VERSION "Emergency_System_CAN_Compat_v2.0"

NS_ :

BS_:

BU_: SIL_TEST_CTRL CHASSIS_GW ACCEL_CTRL BRAKE_CTRL STEERING_CTRL ADAS_WARN_CTRL Vector__XXX VEHICLE_BASE_TEST_CTRL EMS_POLICE_TX EMS_AMB_TX EMS_ALERT_RX BODY_GW BCM_AMBIENT_CTRL HAZARD_CTRL WINDOW_CTRL DRIVER_STATE_CTRL WARN_ARB_MGR INFOTAINMENT_GW IVI_GW NAV_CONTEXT_MGR CLU_HMI_CTRL CLUSTER_BASE_CTRL ENGINE_CTRL TRANSMISSION_CTRL DOMAIN_GW_ROUTER

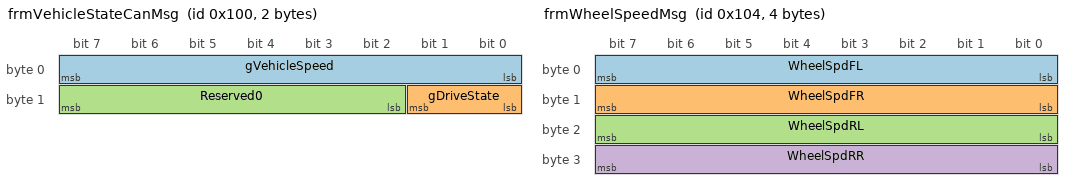
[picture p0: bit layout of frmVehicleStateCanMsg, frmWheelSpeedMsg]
BO_ 256 frmVehicleStateCanMsg: 2 SIL_TEST_CTRL
 SG_ gVehicleSpeed : 0|8@1+ (1,0) [0|255] "km/h" CHASSIS_GW,ADAS_WARN_CTRL
 SG_ gDriveState   : 8|2@1+ (1,0) [0|3]   ""     CHASSIS_GW,ADAS_WARN_CTRL
 SG_ Reserved0     : 10|6@1+ (1,0) [0|0]  ""     Vector__XXX

BO_ 257 frmSteeringCanMsg: 1 SIL_TEST_CTRL
 SG_ SteeringInput : 0|1@1+ (1,0) [0|1] "" CHASSIS_GW,STEERING_CTRL
 SG_ Reserved0     : 1|7@1+ (1,0) [0|0] "" Vector__XXX

BO_ 258 frmPedalInputCanMsg: 2 SIL_TEST_CTRL
 SG_ AccelPedal       : 0|8@1+ (1,0) [0|100] "%" ACCEL_CTRL
 SG_ BrakePedal       : 8|8@1+ (1,0) [0|100] "%" BRAKE_CTRL

BO_ 259 frmSteeringStateCanMsg: 1 CHASSIS_GW
 SG_ SteeringState    : 0|2@1+ (1,0) [0|3] "" STEERING_CTRL
 SG_ Reserved0        : 2|6@1+ (1,0) [0|0] "" Vector__XXX

BO_ 260 frmWheelSpeedMsg: 4 CHASSIS_GW
 SG_ WheelSpdFL       : 0|8@1+ (1,0) [0|255] "km/h" ACCEL_CTRL,BRAKE_CTRL,STEERING_CTRL
 SG_ WheelSpdFR       : 8|8@1+ (1,0) [0|255] "km/h" ACCEL_CTRL,BRAKE_CTRL,STEERING_CTRL
 SG_ WheelSpdRL       : 16|8@1+ (1,0) [0|255] "km/h" ACCEL_CTRL,BRAKE_CTRL,STEERING_CTRL
 SG_ WheelSpdRR       : 24|8@1+ (1,0) [0|255] "km/h" ACCEL_CTRL,BRAKE_CTRL,STEERING_CTRL

BO_ 261 frmYawAccelMsg: 4 CHASSIS_GW
 SG_ YawRate          : 0|16@1+ (1,0) [0|65535] "deg/s" BRAKE_CTRL,STEERING_CTRL
 SG_ LatAccel         : 16|16@1+ (1,0) [0|65535] "0.01m/s2" BRAKE_CTRL,STEERING_CTRL

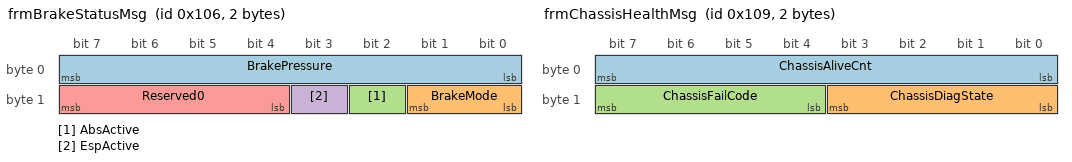
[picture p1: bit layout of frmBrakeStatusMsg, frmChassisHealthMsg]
BO_ 262 frmBrakeStatusMsg: 2 BRAKE_CTRL
 SG_ BrakePressure    : 0|8@1+ (1,0) [0|255] "%" CHASSIS_GW
 SG_ BrakeMode        : 8|2@1+ (1,0) [0|3] "" CHASSIS_GW
 SG_ AbsActive        : 10|1@1+ (1,0) [0|1] "" CHASSIS_GW
 SG_ EspActive        : 11|1@1+ (1,0) [0|1] "" CHASSIS_GW
 SG_ Reserved0        : 12|4@1+ (1,0) [0|0] "" Vector__XXX

BO_ 263 frmAccelStatusMsg: 2 ACCEL_CTRL
 SG_ AccelRequest     : 0|8@1+ (1,0) [0|100] "%" CHASSIS_GW
 SG_ TorqueRequest    : 8|8@1+ (1,0) [0|255] "Nm" CHASSIS_GW

BO_ 264 frmSteeringTorqueMsg: 2 STEERING_CTRL
 SG_ SteeringTorque   : 0|12@1+ (1,0) [0|4095] "0.1Nm" CHASSIS_GW
 SG_ SteeringAssistLv : 12|4@1+ (1,0) [0|15] "" CHASSIS_GW

BO_ 265 frmChassisHealthMsg: 2 CHASSIS_GW
 SG_ ChassisAliveCnt  : 0|8@1+ (1,0) [0|255] "" SIL_TEST_CTRL
 SG_ ChassisDiagState : 8|4@1+ (1,0) [0|15] "" SIL_TEST_CTRL
 SG_ ChassisFailCode  : 12|4@1+ (1,0) [0|15] "" SIL_TEST_CTRL

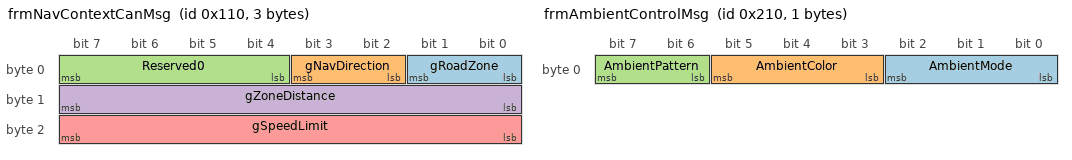
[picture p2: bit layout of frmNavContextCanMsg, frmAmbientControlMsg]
BO_ 272 frmNavContextCanMsg: 3 SIL_TEST_CTRL
 SG_ gRoadZone     : 0|2@1+ (1,0) [0|3]    "" INFOTAINMENT_GW,NAV_CONTEXT_MGR
 SG_ gNavDirection : 2|2@1+ (1,0) [0|3]    "" INFOTAINMENT_GW,NAV_CONTEXT_MGR
 SG_ Reserved0     : 4|4@1+ (1,0) [0|0]    "" Vector__XXX
 SG_ gZoneDistance : 8|8@1+ (1,0) [0|255]  "m" INFOTAINMENT_GW,NAV_CONTEXT_MGR
 SG_ gSpeedLimit   : 16|8@1+ (1,0) [0|255] "km/h" INFOTAINMENT_GW,NAV_CONTEXT_MGR

BO_ 528 frmAmbientControlMsg: 1 BODY_GW
 SG_ AmbientMode    : 0|3@1+ (1,0) [0|7] "" BCM_AMBIENT_CTRL
 SG_ AmbientColor   : 3|3@1+ (1,0) [0|7] "" BCM_AMBIENT_CTRL
 SG_ AmbientPattern : 6|2@1+ (1,0) [0|3] "" BCM_AMBIENT_CTRL

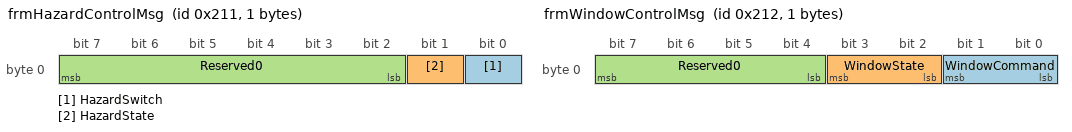
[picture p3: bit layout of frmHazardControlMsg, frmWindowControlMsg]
BO_ 529 frmHazardControlMsg: 1 BODY_GW
 SG_ HazardSwitch     : 0|1@1+ (1,0) [0|1] "" HAZARD_CTRL
 SG_ HazardState      : 1|1@1+ (1,0) [0|1] "" HAZARD_CTRL
 SG_ Reserved0        : 2|6@1+ (1,0) [0|0] "" Vector__XXX

BO_ 530 frmWindowControlMsg: 1 BODY_GW
 SG_ WindowCommand    : 0|2@1+ (1,0) [0|3] "" WINDOW_CTRL
 SG_ WindowState      : 2|2@1+ (1,0) [0|3] "" WINDOW_CTRL
 SG_ Reserved0        : 4|4@1+ (1,0) [0|0] "" Vector__XXX

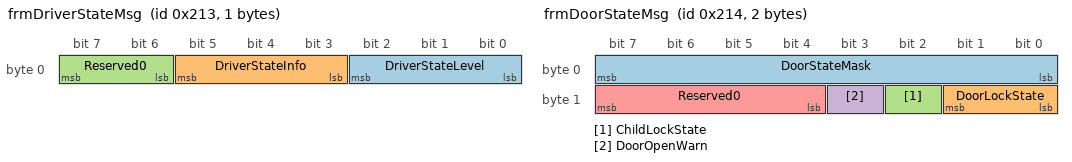
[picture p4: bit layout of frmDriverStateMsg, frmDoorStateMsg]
BO_ 531 frmDriverStateMsg: 1 BODY_GW
 SG_ DriverStateLevel : 0|3@1+ (1,0) [0|7] "" DRIVER_STATE_CTRL
 SG_ DriverStateInfo  : 3|3@1+ (1,0) [0|7] "" DRIVER_STATE_CTRL
 SG_ Reserved0        : 6|2@1+ (1,0) [0|0] "" Vector__XXX

BO_ 532 frmDoorStateMsg: 2 BODY_GW
 SG_ DoorStateMask    : 0|8@1+ (1,0) [0|255] "" WINDOW_CTRL,DRIVER_STATE_CTRL
 SG_ DoorLockState    : 8|2@1+ (1,0) [0|3] "" WINDOW_CTRL,DRIVER_STATE_CTRL
 SG_ ChildLockState   : 10|1@1+ (1,0) [0|1] "" WINDOW_CTRL,DRIVER_STATE_CTRL
 SG_ DoorOpenWarn     : 11|1@1+ (1,0) [0|1] "" WINDOW_CTRL,DRIVER_STATE_CTRL
 SG_ Reserved0        : 12|4@1+ (1,0) [0|0] "" Vector__XXX

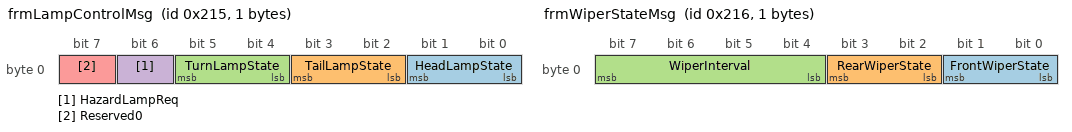
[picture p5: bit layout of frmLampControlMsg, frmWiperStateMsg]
BO_ 533 frmLampControlMsg: 1 BODY_GW
 SG_ HeadLampState    : 0|2@1+ (1,0) [0|3] "" BCM_AMBIENT_CTRL
 SG_ TailLampState    : 2|2@1+ (1,0) [0|3] "" BCM_AMBIENT_CTRL
 SG_ TurnLampState    : 4|2@1+ (1,0) [0|3] "" BCM_AMBIENT_CTRL
 SG_ HazardLampReq    : 6|1@1+ (1,0) [0|1] "" HAZARD_CTRL
 SG_ Reserved0        : 7|1@1+ (1,0) [0|0] "" Vector__XXX

BO_ 534 frmWiperStateMsg: 1 BODY_GW
 SG_ FrontWiperState  : 0|2@1+ (1,0) [0|3] "" BCM_AMBIENT_CTRL
 SG_ RearWiperState   : 2|2@1+ (1,0) [0|3] "" BCM_AMBIENT_CTRL
 SG_ WiperInterval    : 4|4@1+ (1,0) [0|15] "" BCM_AMBIENT_CTRL

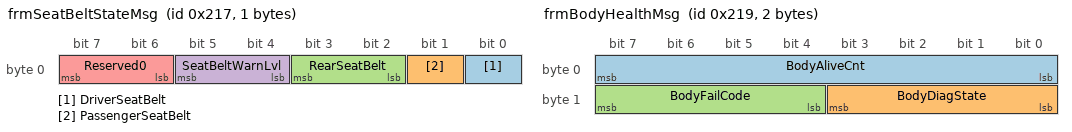
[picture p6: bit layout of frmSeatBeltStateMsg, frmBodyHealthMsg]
BO_ 535 frmSeatBeltStateMsg: 1 DRIVER_STATE_CTRL
 SG_ DriverSeatBelt   : 0|1@1+ (1,0) [0|1] "" BODY_GW,BCM_AMBIENT_CTRL
 SG_ PassengerSeatBelt : 1|1@1+ (1,0) [0|1] "" BODY_GW,BCM_AMBIENT_CTRL
 SG_ RearSeatBelt     : 2|2@1+ (1,0) [0|3] "" BODY_GW,BCM_AMBIENT_CTRL
 SG_ SeatBeltWarnLvl  : 4|2@1+ (1,0) [0|3] "" BODY_GW,BCM_AMBIENT_CTRL
 SG_ Reserved0        : 6|2@1+ (1,0) [0|0] "" Vector__XXX

BO_ 536 frmCabinAirStateMsg: 2 DRIVER_STATE_CTRL
 SG_ CabinTemp        : 0|8@1+ (1,0) [0|100] "degC" BODY_GW
 SG_ AirQualityIndex  : 8|8@1+ (1,0) [0|255] "" BODY_GW

BO_ 537 frmBodyHealthMsg: 2 BODY_GW
 SG_ BodyAliveCnt     : 0|8@1+ (1,0) [0|255] "" SIL_TEST_CTRL
 SG_ BodyDiagState    : 8|4@1+ (1,0) [0|15] "" SIL_TEST_CTRL
 SG_ BodyFailCode     : 12|4@1+ (1,0) [0|15] "" SIL_TEST_CTRL

BO_ 544 frmClusterWarningMsg: 1 IVI_GW
 SG_ WarningTextCode : 0|8@1+ (1,0) [0|255] "" CLU_HMI_CTRL

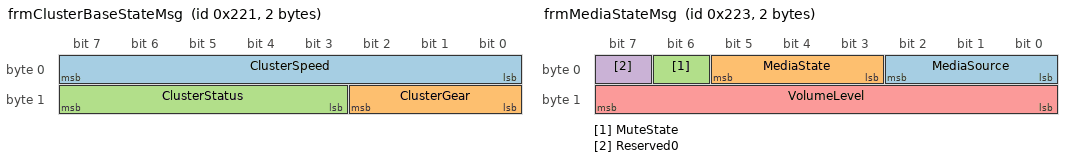
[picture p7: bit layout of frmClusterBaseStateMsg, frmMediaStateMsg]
BO_ 545 frmClusterBaseStateMsg: 2 IVI_GW
 SG_ ClusterSpeed     : 0|8@1+ (1,0) [0|255] "km/h" CLUSTER_BASE_CTRL
 SG_ ClusterGear      : 8|3@1+ (1,0) [0|7] "" CLUSTER_BASE_CTRL
 SG_ ClusterStatus    : 11|5@1+ (1,0) [0|31] "" CLUSTER_BASE_CTRL

BO_ 546 frmNaviGuideStateMsg: 1 INFOTAINMENT_GW
 SG_ GuideLaneState   : 0|2@1+ (1,0) [0|3] "" NAV_CONTEXT_MGR
 SG_ GuideConfidence  : 2|6@1+ (1,0) [0|63] "" NAV_CONTEXT_MGR

BO_ 547 frmMediaStateMsg: 2 IVI_GW
 SG_ MediaSource      : 0|3@1+ (1,0) [0|7] "" CLU_HMI_CTRL
 SG_ MediaState       : 3|3@1+ (1,0) [0|7] "" CLU_HMI_CTRL
 SG_ MuteState        : 6|1@1+ (1,0) [0|1] "" CLU_HMI_CTRL
 SG_ Reserved0        : 7|1@1+ (1,0) [0|0] "" Vector__XXX
 SG_ VolumeLevel      : 8|8@1+ (1,0) [0|100] "%" CLU_HMI_CTRL

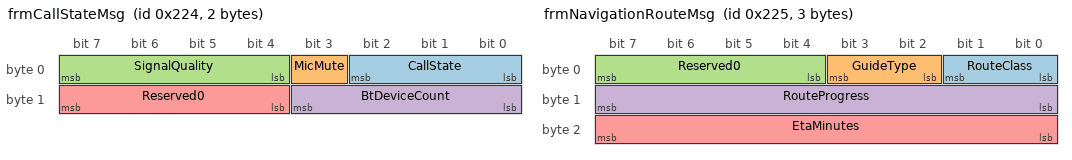
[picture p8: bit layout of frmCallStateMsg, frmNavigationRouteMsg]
BO_ 548 frmCallStateMsg: 2 IVI_GW
 SG_ CallState        : 0|3@1+ (1,0) [0|7] "" CLU_HMI_CTRL
 SG_ MicMute          : 3|1@1+ (1,0) [0|1] "" CLU_HMI_CTRL
 SG_ SignalQuality    : 4|4@1+ (1,0) [0|15] "" CLU_HMI_CTRL
 SG_ BtDeviceCount    : 8|4@1+ (1,0) [0|15] "" CLU_HMI_CTRL
 SG_ Reserved0        : 12|4@1+ (1,0) [0|0] "" Vector__XXX

BO_ 549 frmNavigationRouteMsg: 3 INFOTAINMENT_GW
 SG_ RouteClass       : 0|2@1+ (1,0) [0|3] "" NAV_CONTEXT_MGR
 SG_ GuideType        : 2|2@1+ (1,0) [0|3] "" NAV_CONTEXT_MGR
 SG_ Reserved0        : 4|4@1+ (1,0) [0|0] "" Vector__XXX
 SG_ RouteProgress    : 8|8@1+ (1,0) [0|100] "%" NAV_CONTEXT_MGR
 SG_ EtaMinutes       : 16|8@1+ (1,0) [0|255] "min" NAV_CONTEXT_MGR

BO_ 550 frmClusterThemeMsg: 1 IVI_GW
 SG_ ThemeMode        : 0|3@1+ (1,0) [0|7] "" CLUSTER_BASE_CTRL
 SG_ ClusterBrightness : 3|5@1+ (1,0) [0|31] "" CLUSTER_BASE_CTRL

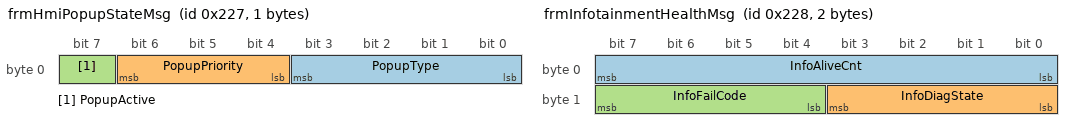
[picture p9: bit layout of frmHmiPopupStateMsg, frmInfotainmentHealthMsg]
BO_ 551 frmHmiPopupStateMsg: 1 IVI_GW
 SG_ PopupType        : 0|4@1+ (1,0) [0|15] "" CLU_HMI_CTRL
 SG_ PopupPriority    : 4|3@1+ (1,0) [0|7] "" CLU_HMI_CTRL
 SG_ PopupActive      : 7|1@1+ (1,0) [0|1] "" CLU_HMI_CTRL

BO_ 552 frmInfotainmentHealthMsg: 2 INFOTAINMENT_GW
 SG_ InfoAliveCnt     : 0|8@1+ (1,0) [0|255] "" SIL_TEST_CTRL
 SG_ InfoDiagState    : 8|4@1+ (1,0) [0|15] "" SIL_TEST_CTRL
 SG_ InfoFailCode     : 12|4@1+ (1,0) [0|15] "" SIL_TEST_CTRL

BO_ 560 frmTestResultMsg: 1 SIL_TEST_CTRL
 SG_ ScenarioResult : 0|1@1+ (1,0) [0|1] "" VEHICLE_BASE_TEST_CTRL
 SG_ Reserved0      : 1|7@1+ (1,0) [0|0] "" Vector__XXX

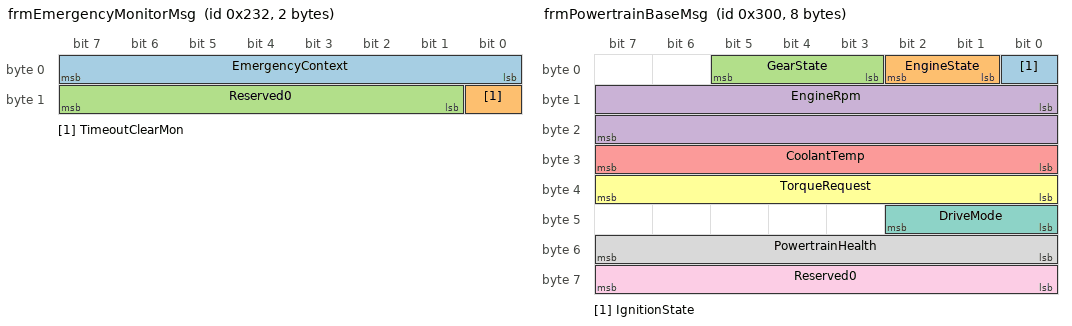
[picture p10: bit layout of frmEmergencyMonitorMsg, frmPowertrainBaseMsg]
BO_ 562 frmEmergencyMonitorMsg: 2 EMS_ALERT_RX
 SG_ EmergencyContext : 0|8@1+ (1,0) [0|255] "" SIL_TEST_CTRL,CHASSIS_GW
 SG_ TimeoutClearMon  : 8|1@1+ (1,0) [0|1] "" SIL_TEST_CTRL,CHASSIS_GW
 SG_ Reserved0        : 9|7@1+ (1,0) [0|0] "" Vector__XXX

BO_ 768 frmPowertrainBaseMsg: 8 ENGINE_CTRL
 SG_ IgnitionState   : 0|1@1+ (1,0) [0|1] "" SIL_TEST_CTRL,CHASSIS_GW
 SG_ EngineState     : 1|2@1+ (1,0) [0|3] "" SIL_TEST_CTRL,CHASSIS_GW
 SG_ GearState       : 3|3@1+ (1,0) [0|7] "" SIL_TEST_CTRL,CHASSIS_GW
 SG_ EngineRpm       : 8|16@1+ (1,0) [0|65535] "rpm" CHASSIS_GW,DOMAIN_GW_ROUTER
 SG_ CoolantTemp     : 24|8@1+ (1,0) [0|255] "degC" DOMAIN_GW_ROUTER
 SG_ TorqueRequest   : 32|8@1+ (1,0) [0|255] "Nm" DOMAIN_GW_ROUTER
 SG_ DriveMode       : 40|3@1+ (1,0) [0|7] "" DOMAIN_GW_ROUTER
 SG_ PowertrainHealth: 48|8@1+ (1,0) [0|255] "" DOMAIN_GW_ROUTER
 SG_ Reserved0       : 56|8@1+ (1,0) [0|0] "" Vector__XXX

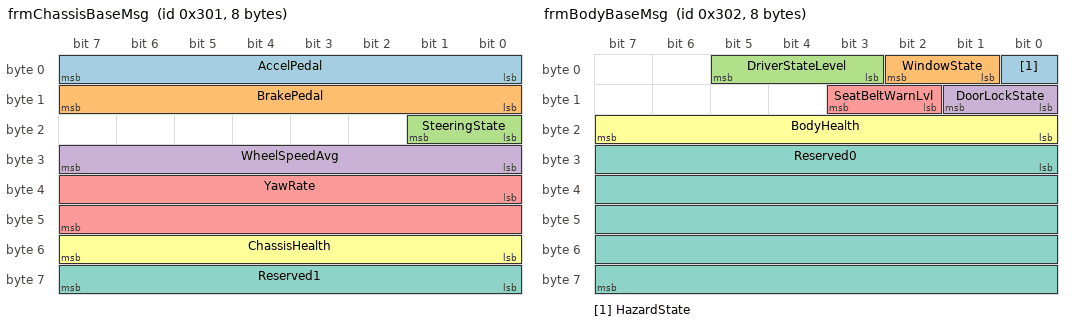
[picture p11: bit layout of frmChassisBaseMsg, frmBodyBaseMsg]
BO_ 769 frmChassisBaseMsg: 8 CHASSIS_GW
 SG_ AccelPedal      : 0|8@1+ (1,0) [0|100] "%" ACCEL_CTRL,ADAS_WARN_CTRL
 SG_ BrakePedal      : 8|8@1+ (1,0) [0|100] "%" BRAKE_CTRL,ADAS_WARN_CTRL
 SG_ SteeringState   : 16|2@1+ (1,0) [0|3]  "" STEERING_CTRL,ADAS_WARN_CTRL
 SG_ WheelSpeedAvg   : 24|8@1+ (1,0) [0|255] "km/h" ADAS_WARN_CTRL
 SG_ YawRate         : 32|16@1+ (1,0) [0|65535] "deg/s" ADAS_WARN_CTRL
 SG_ ChassisHealth   : 48|8@1+ (1,0) [0|255] "" ADAS_WARN_CTRL
 SG_ Reserved1       : 56|8@1+ (1,0) [0|0] "" Vector__XXX

BO_ 770 frmBodyBaseMsg: 8 BODY_GW
 SG_ HazardState      : 0|1@1+ (1,0) [0|1] "" HAZARD_CTRL
 SG_ WindowState      : 1|2@1+ (1,0) [0|3] "" WINDOW_CTRL
 SG_ DriverStateLevel : 3|3@1+ (1,0) [0|7] "" DRIVER_STATE_CTRL
 SG_ DoorLockState    : 8|2@1+ (1,0) [0|3] "" WINDOW_CTRL
 SG_ SeatBeltWarnLvl  : 10|2@1+ (1,0) [0|3] "" DRIVER_STATE_CTRL
 SG_ BodyHealth       : 16|8@1+ (1,0) [0|255] "" WARN_ARB_MGR
 SG_ Reserved0        : 24|40@1+ (1,0) [0|0] "" Vector__XXX

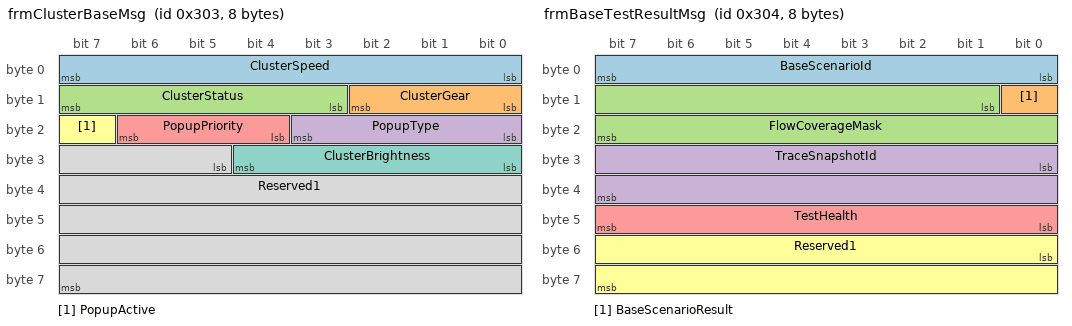
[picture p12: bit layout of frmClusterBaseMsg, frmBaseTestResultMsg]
BO_ 771 frmClusterBaseMsg: 8 IVI_GW
 SG_ ClusterSpeed      : 0|8@1+ (1,0) [0|255] "km/h" CLUSTER_BASE_CTRL
 SG_ ClusterGear       : 8|3@1+ (1,0) [0|7]   "" CLUSTER_BASE_CTRL
 SG_ ClusterStatus     : 11|5@1+ (1,0) [0|31] "" CLUSTER_BASE_CTRL
 SG_ PopupType         : 16|4@1+ (1,0) [0|15] "" CLU_HMI_CTRL
 SG_ PopupPriority     : 20|3@1+ (1,0) [0|7]  "" CLU_HMI_CTRL
 SG_ PopupActive       : 23|1@1+ (1,0) [0|1]  "" CLU_HMI_CTRL
 SG_ ClusterBrightness : 24|5@1+ (1,0) [0|31] "" CLUSTER_BASE_CTRL
 SG_ Reserved1         : 29|35@1+ (1,0) [0|0] "" Vector__XXX

BO_ 772 frmBaseTestResultMsg: 8 VEHICLE_BASE_TEST_CTRL
 SG_ BaseScenarioId    : 0|8@1+ (1,0) [0|255] "" SIL_TEST_CTRL
 SG_ BaseScenarioResult: 8|1@1+ (1,0) [0|1]   "" SIL_TEST_CTRL
 SG_ FlowCoverageMask  : 9|15@1+ (1,0) [0|32767] "" SIL_TEST_CTRL
 SG_ TraceSnapshotId   : 24|16@1+ (1,0) [0|65535] "" SIL_TEST_CTRL
 SG_ TestHealth        : 40|8@1+ (1,0) [0|255] "" SIL_TEST_CTRL
 SG_ Reserved1         : 48|16@1+ (1,0) [0|0] "" Vector__XXX

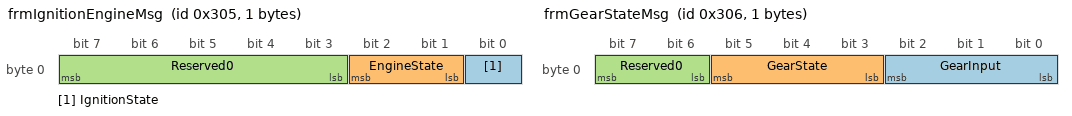
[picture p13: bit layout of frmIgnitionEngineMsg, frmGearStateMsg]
BO_ 773 frmIgnitionEngineMsg: 1 SIL_TEST_CTRL
 SG_ IgnitionState  : 0|1@1+ (1,0) [0|1] "" ENGINE_CTRL
 SG_ EngineState    : 1|2@1+ (1,0) [0|3] "" ENGINE_CTRL
 SG_ Reserved0      : 3|5@1+ (1,0) [0|0] "" Vector__XXX

BO_ 774 frmGearStateMsg: 1 SIL_TEST_CTRL
 SG_ GearInput      : 0|3@1+ (1,0) [0|7] "" TRANSMISSION_CTRL
 SG_ GearState      : 3|3@1+ (1,0) [0|7] "" TRANSMISSION_CTRL
 SG_ Reserved0      : 6|2@1+ (1,0) [0|0] "" Vector__XXX

BO_ 775 frmPowertrainGatewayMsg: 2 DOMAIN_GW_ROUTER
 SG_ RoutingPolicy  : 0|8@1+ (1,0) [0|255] "" ENGINE_CTRL,TRANSMISSION_CTRL
 SG_ BoundaryStatus : 8|8@1+ (1,0) [0|255] "" ENGINE_CTRL,TRANSMISSION_CTRL

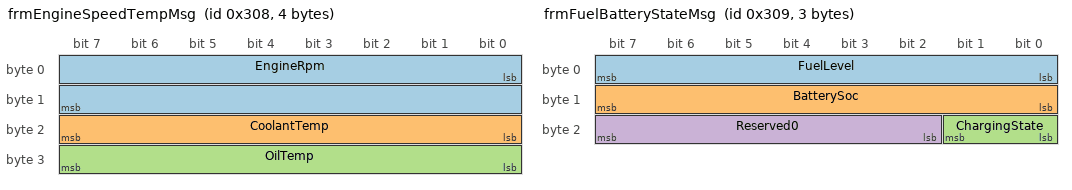
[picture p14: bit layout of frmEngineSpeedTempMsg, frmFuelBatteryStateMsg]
BO_ 776 frmEngineSpeedTempMsg: 4 ENGINE_CTRL
 SG_ EngineRpm       : 0|16@1+ (1,0) [0|65535] "rpm" TRANSMISSION_CTRL,DOMAIN_GW_ROUTER
 SG_ CoolantTemp     : 16|8@1+ (1,0) [0|255] "degC" TRANSMISSION_CTRL,DOMAIN_GW_ROUTER
 SG_ OilTemp         : 24|8@1+ (1,0) [0|255] "degC" TRANSMISSION_CTRL,DOMAIN_GW_ROUTER

BO_ 777 frmFuelBatteryStateMsg: 3 ENGINE_CTRL
 SG_ FuelLevel       : 0|8@1+ (1,0) [0|100] "%" DOMAIN_GW_ROUTER
 SG_ BatterySoc      : 8|8@1+ (1,0) [0|100] "%" DOMAIN_GW_ROUTER
 SG_ ChargingState   : 16|2@1+ (1,0) [0|3] "" DOMAIN_GW_ROUTER
 SG_ Reserved0       : 18|6@1+ (1,0) [0|0] "" Vector__XXX

BO_ 778 frmThrottleStateMsg: 2 ENGINE_CTRL
 SG_ ThrottlePos     : 0|8@1+ (1,0) [0|100] "%" TRANSMISSION_CTRL,DOMAIN_GW_ROUTER
 SG_ ThrottleReq     : 8|8@1+ (1,0) [0|100] "%" TRANSMISSION_CTRL,DOMAIN_GW_ROUTER

BO_ 779 frmTransmissionTempMsg: 2 TRANSMISSION_CTRL
 SG_ TransOilTemp    : 0|8@1+ (1,0) [0|255] "degC" ENGINE_CTRL,DOMAIN_GW_ROUTER
 SG_ ClutchTemp      : 8|8@1+ (1,0) [0|255] "degC" ENGINE_CTRL,DOMAIN_GW_ROUTER

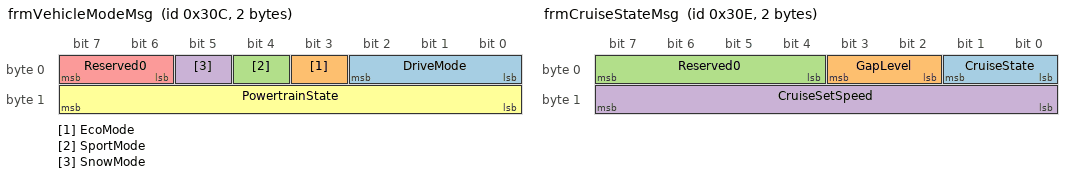
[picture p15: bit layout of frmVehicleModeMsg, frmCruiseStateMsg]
BO_ 780 frmVehicleModeMsg: 2 DOMAIN_GW_ROUTER
 SG_ DriveMode       : 0|3@1+ (1,0) [0|7] "" ENGINE_CTRL,TRANSMISSION_CTRL
 SG_ EcoMode         : 3|1@1+ (1,0) [0|1] "" ENGINE_CTRL,TRANSMISSION_CTRL
 SG_ SportMode       : 4|1@1+ (1,0) [0|1] "" ENGINE_CTRL,TRANSMISSION_CTRL
 SG_ SnowMode        : 5|1@1+ (1,0) [0|1] "" ENGINE_CTRL,TRANSMISSION_CTRL
 SG_ Reserved0       : 6|2@1+ (1,0) [0|0] "" Vector__XXX
 SG_ PowertrainState : 8|8@1+ (1,0) [0|255] "" ENGINE_CTRL,TRANSMISSION_CTRL

BO_ 781 frmPowerLimitMsg: 2 DOMAIN_GW_ROUTER
 SG_ TorqueLimit     : 0|8@1+ (1,0) [0|255] "Nm" ENGINE_CTRL,TRANSMISSION_CTRL
 SG_ SpeedLimit      : 8|8@1+ (1,0) [0|255] "km/h" ENGINE_CTRL,TRANSMISSION_CTRL

BO_ 782 frmCruiseStateMsg: 2 DOMAIN_GW_ROUTER
 SG_ CruiseState     : 0|2@1+ (1,0) [0|3] "" ENGINE_CTRL,TRANSMISSION_CTRL
 SG_ GapLevel        : 2|2@1+ (1,0) [0|3] "" ENGINE_CTRL,TRANSMISSION_CTRL
 SG_ Reserved0       : 4|4@1+ (1,0) [0|0] "" Vector__XXX
 SG_ CruiseSetSpeed  : 8|8@1+ (1,0) [0|255] "km/h" ENGINE_CTRL,TRANSMISSION_CTRL

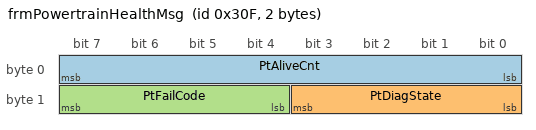
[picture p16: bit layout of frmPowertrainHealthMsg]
BO_ 783 frmPowertrainHealthMsg: 2 DOMAIN_GW_ROUTER
 SG_ PtAliveCnt      : 0|8@1+ (1,0) [0|255] "" SIL_TEST_CTRL
 SG_ PtDiagState     : 8|4@1+ (1,0) [0|15] "" SIL_TEST_CTRL
 SG_ PtFailCode      : 12|4@1+ (1,0) [0|15] "" SIL_TEST_CTRL

CM_ "Compatibility aggregate DBC for legacy CANoe cfg (CAN_500kBaud_1ch.cfg).";
CM_ "Source of truth remains split canonical DBCs: chassis/body/infotainment/powertrain/test.";
CM_ BO_ 256 "Flow_001 core vehicle state input.";
CM_ BO_ 257 "Flow_002 steering input.";
CM_ BO_ 258 "Chassis baseline: acceleration pedal and brake pedal input.";
CM_ BO_ 259 "Chassis baseline: steering state produced from normalized steering input.";
CM_ BO_ 260 "Chassis baseline: per-wheel speed distribution.";
CM_ BO_ 261 "Chassis baseline: yaw rate and lateral acceleration.";
CM_ BO_ 262 "Chassis baseline: brake pressure and ESC/ABS status.";
CM_ BO_ 263 "Chassis baseline: acceleration request and torque request.";
CM_ BO_ 264 "Chassis baseline: steering torque and assist level.";
CM_ BO_ 265 "Chassis health/diagnostic state.";
CM_ BO_ 272 "Flow_003 navigation context input.";
CM_ BO_ 528 "Flow_007 ambient output.";
CM_ BO_ 529 "Body baseline: hazard switch and hazard state.";
CM_ BO_ 530 "Body baseline: window command and window state.";
CM_ BO_ 531 "Body baseline: driver state level and state info.";
CM_ BO_ 532 "Body baseline: door mask/lock/child-lock/open-warning state.";
CM_ BO_ 533 "Body baseline: lamp and hazard request state.";
CM_ BO_ 534 "Body baseline: front/rear wiper state and interval.";
CM_ BO_ 535 "Body baseline: seat-belt occupancy and warning level.";
CM_ BO_ 536 "Body baseline: cabin temperature and air quality index.";
CM_ BO_ 537 "Body health/diagnostic state.";
CM_ BO_ 544 "Flow_008 cluster warning output.";
CM_ BO_ 545 "Infotainment baseline: cluster base display payload (speed/gear/status).";
CM_ BO_ 546 "Infotainment baseline: lane guidance state and confidence.";
CM_ BO_ 547 "Infotainment baseline: media source/state/mute/volume.";
CM_ BO_ 548 "Infotainment baseline: call state, mute, and signal quality.";
CM_ BO_ 549 "Infotainment baseline: route class/progress/ETA.";
CM_ BO_ 550 "Infotainment baseline: cluster theme and brightness.";
CM_ BO_ 551 "Infotainment baseline: popup type/priority/active flag.";
CM_ BO_ 552 "Infotainment health/diagnostic state.";
CM_ BO_ 560 "Comm_009 scenario result frame.";
CM_ BO_ 562 "Emergency context monitor shadow frame for SIL CAN tracing.";
CM_ BO_ 768 "Comm_101 baseline powertrain aggregate message (Req_101~Req_102).";
CM_ BO_ 769 "Comm_102 baseline chassis aggregate message (Req_103~Req_105).";
CM_ BO_ 770 "Comm_103 baseline body aggregate message (Req_106~Req_108).";
CM_ BO_ 771 "Comm_104 baseline cluster aggregate message (Req_109).";
CM_ BO_ 772 "Comm_106 baseline test aggregate result frame (Req_112).";
CM_ BO_ 773 "Powertrain baseline: ignition state and engine state.";
CM_ BO_ 774 "Powertrain baseline: gear input and gear state.";
CM_ BO_ 775 "Powertrain baseline: domain routing policy and boundary status.";
CM_ BO_ 776 "Powertrain baseline: engine RPM and thermal state.";
CM_ BO_ 777 "Powertrain baseline: fuel and battery state.";
CM_ BO_ 778 "Powertrain baseline: throttle position and request.";
CM_ BO_ 779 "Powertrain baseline: transmission thermal state.";
CM_ BO_ 780 "Powertrain baseline: drive mode and powertrain state.";
CM_ BO_ 781 "Powertrain baseline: torque and speed limits.";
CM_ BO_ 782 "Powertrain baseline: cruise state, gap, and set speed.";
CM_ BO_ 783 "Powertrain health/diagnostic state.";

BA_DEF_ BO_ "GenMsgCycleTime" INT 0 10000;
BA_DEF_DEF_ "GenMsgCycleTime" 0;
BA_ "GenMsgCycleTime" BO_ 256 100;
BA_ "GenMsgCycleTime" BO_ 257 100;
BA_ "GenMsgCycleTime" BO_ 258 100;
BA_ "GenMsgCycleTime" BO_ 259 100;
BA_ "GenMsgCycleTime" BO_ 260 100;
BA_ "GenMsgCycleTime" BO_ 261 100;
BA_ "GenMsgCycleTime" BO_ 262 100;
BA_ "GenMsgCycleTime" BO_ 263 100;
BA_ "GenMsgCycleTime" BO_ 264 100;
BA_ "GenMsgCycleTime" BO_ 265 100;
BA_ "GenMsgCycleTime" BO_ 272 100;
BA_ "GenMsgCycleTime" BO_ 528 50;
BA_ "GenMsgCycleTime" BO_ 529 100;
BA_ "GenMsgCycleTime" BO_ 530 100;
BA_ "GenMsgCycleTime" BO_ 531 100;
BA_ "GenMsgCycleTime" BO_ 532 100;
BA_ "GenMsgCycleTime" BO_ 533 100;
BA_ "GenMsgCycleTime" BO_ 534 100;
BA_ "GenMsgCycleTime" BO_ 535 100;
BA_ "GenMsgCycleTime" BO_ 536 100;
BA_ "GenMsgCycleTime" BO_ 537 100;
BA_ "GenMsgCycleTime" BO_ 544 50;
BA_ "GenMsgCycleTime" BO_ 545 50;
BA_ "GenMsgCycleTime" BO_ 546 100;
BA_ "GenMsgCycleTime" BO_ 547 100;
BA_ "GenMsgCycleTime" BO_ 548 100;
BA_ "GenMsgCycleTime" BO_ 549 100;
BA_ "GenMsgCycleTime" BO_ 550 50;
BA_ "GenMsgCycleTime" BO_ 551 50;
BA_ "GenMsgCycleTime" BO_ 552 100;
BA_ "GenMsgCycleTime" BO_ 562 100;
BA_ "GenMsgCycleTime" BO_ 768 100;
BA_ "GenMsgCycleTime" BO_ 769 100;
BA_ "GenMsgCycleTime" BO_ 770 100;
BA_ "GenMsgCycleTime" BO_ 771 50;
BA_ "GenMsgCycleTime" BO_ 773 100;
BA_ "GenMsgCycleTime" BO_ 774 100;
BA_ "GenMsgCycleTime" BO_ 775 100;
BA_ "GenMsgCycleTime" BO_ 776 100;
BA_ "GenMsgCycleTime" BO_ 777 100;
BA_ "GenMsgCycleTime" BO_ 778 100;
BA_ "GenMsgCycleTime" BO_ 779 100;
BA_ "GenMsgCycleTime" BO_ 780 100;
BA_ "GenMsgCycleTime" BO_ 781 100;
BA_ "GenMsgCycleTime" BO_ 782 100;
BA_ "GenMsgCycleTime" BO_ 783 100;

  0 "P"
  1 "R"
  2 "N"
  3 "D" ;

  0 "NoInput"
  1 "Input" ;

  0 "Stable"
  1 "LeftTurn"
  2 "RightTurn"
  3 "Fault" ;

  0 "Normal"
  1 "Assist"
  2 "Emergency"
  3 "Fault" ;

  0 "Inactive"
  1 "Active" ;

  0 "Inactive"
  1 "Active" ;

  0 "Normal"
  1 "SchoolZone"
  2 "Highway"
  3 "Guide" ;

  0 "None"
  1 "Left"
  2 "Right"
  3 "Other" ;

  0 "Off"
  1 "Basic"
  2 "Caution"
  3 "SchoolZone"
  4 "Reserved"
  5 "GuideLeft"
  6 "GuideRight"
  7 "Emergency" ;

  0 "Off"
  1 "On" ;

  0 "Inactive"
  1 "Active" ;

  0 "NoCmd"
  1 "Open"
  2 "Close"
  3 "Stop" ;

  0 "Unknown"
  1 "Opened"
  2 "Closed"
  3 "Moving" ;

  0 "Normal"
  1 "MildDrowsy"
  2 "Drowsy"
  3 "Distracted"
  4 "Critical"
  5 "Reserved5"
  6 "Reserved6"
  7 "Reserved7" ;

  0 "Unlocked"
  1 "Locked"
  2 "AutoLock"
  3 "Fault" ;

  0 "Off"
  1 "On" ;

  0 "NoWarn"
  1 "Warn" ;

  0 "Off"
  1 "Parking"
  2 "LowBeam"
  3 "HighBeam" ;

  0 "Off"
  1 "On"
  2 "Auto"
  3 "Fault" ;

  0 "Off"
  1 "Left"
  2 "Right"
  3 "Hazard" ;

  0 "Off"
  1 "On" ;

  0 "Off"
  1 "Low"
  2 "High"
  3 "Auto" ;

  0 "Off"
  1 "On"
  2 "Intermittent"
  3 "Fault" ;

  0 "Unbuckled"
  1 "Buckled" ;

  0 "Unbuckled"
  1 "Buckled" ;

  0 "None"
  1 "SomeUnbuckled"
  2 "AllBuckled"
  3 "Fault" ;

  0 "None"
  1 "Info"
  2 "Warn"
  3 "Critical" ;

  0 "None"
  1 "Left"
  2 "Right"
  3 "Merge" ;

  0 "None"
  1 "Radio"
  2 "Bluetooth"
  3 "USB"
  4 "Streaming"
  5 "NaviVoice"
  6 "Reserved6"
  7 "Reserved7" ;

  0 "Stopped"
  1 "Playing"
  2 "Paused"
  3 "Buffering"
  4 "Error"
  5 "Reserved5"
  6 "Reserved6"
  7 "Reserved7" ;

  0 "Unmuted"
  1 "Muted" ;

  0 "Idle"
  1 "Ringing"
  2 "Connected"
  3 "OnHold"
  4 "Ended"
  5 "Reserved5"
  6 "Reserved6"
  7 "Reserved7" ;

  0 "Off"
  1 "On" ;

  0 "Local"
  1 "Primary"
  2 "Highway"
  3 "Mixed" ;

  0 "None"
  1 "Turn"
  2 "LaneChange"
  3 "Exit" ;

  0 "Default"
  1 "Sport"
  2 "Comfort"
  3 "Eco"
  4 "Night"
  5 "Alert"
  6 "Reserved6"
  7 "Reserved7" ;

  0 "Inactive"
  1 "Active" ;

  0 "Fail"
  1 "Pass" ;

  0 "NoClear"
  1 "Clear" ;

  0 "Off"
  1 "On" ;

  0 "Off"
  1 "Starting"
  2 "Running"
  3 "Fault" ;

  0 "Normal"
  1 "Eco"
  2 "Sport"
  3 "Snow"
  4 "Comfort"
  5 "Custom"
  6 "Reserved6"
  7 "Reserved7" ;

  0 "Fail"
  1 "Pass" ;

  0 "Off"
  1 "On" ;

  0 "Off"
  1 "Starting"
  2 "Running"
  3 "Fault" ;

  0 "P"
  1 "R"
  2 "N"
  3 "D"
  4 "S"
  5 "M"
  6 "Reserved6"
  7 "Reserved7" ;

  0 "P"
  1 "R"
  2 "N"
  3 "D"
  4 "S"
  5 "M"
  6 "Reserved6"
  7 "Reserved7" ;

  0 "Idle"
  1 "Charging"
  2 "Discharging"
  3 "Fault" ;

  0 "Normal"
  1 "Eco"
  2 "Sport"
  3 "Snow"
  4 "Comfort"
  5 "Custom"
  6 "Reserved6"
  7 "Reserved7" ;

  0 "Off"
  1 "On" ;

  0 "Off"
  1 "On" ;

  0 "Off"
  1 "On" ;

  0 "Off"
  1 "Standby"
  2 "Active"
  3 "Fault" ;
